AUTOSAR XML (schema 00053)
package /Application
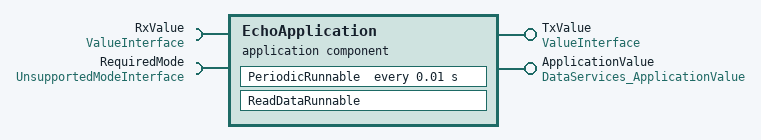
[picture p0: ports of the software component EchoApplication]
  application sw component type EchoApplication
    require port RxValue: nonqueued-receiver-com-spec{data-element=Value, alive-timeout=0.03, handle-never-received=true, init-value=0}, required-interface=ValueInterface
    provide port TxValue: nonqueued-sender-com-spec{data-element=Value, init-value=0}, provided-interface=ValueInterface
    provide port ApplicationValue: server-com-spec{operation=ReadData, queue-length=1}, provided-interface=DataServices_ApplicationValue
    require port RequiredMode: required-interface=UnsupportedModeInterface
    behavior Behavior: data-type-mapping=ApplicationTypes
      timing event Periodic10ms: start-on-event=PeriodicRunnable, period=0.01
      operation invoked event ReadApplicationValue: start-on-event=ReadDataRunnable, operation=ApplicationValue.ReadData
      runnable PeriodicRunnable: symbol=EchoApplication_Periodic
        data-receive-point-by-arguments:
          access ReadRxValue: accessed-variable=RxValue.Value
        data-send-points:
          access WriteTxValue: accessed-variable=TxValue.Value
        mode-access-point mode-group=RequiredMode.Mode:
          ident ReadMode
      runnable ReadDataRunnable: symbol=EchoApplication_ReadData
  composition sw component type ReferenceComposition
    component EchoApplication: type=EchoApplication
    component DcmService: type=DcmService
    connect EchoApplication.ApplicationValue -> DcmService.ApplicationValue
  mode declaration group UnsupportedModes: initial-mode=Idle
    mode Idle
  mode switch interface UnsupportedModeInterface
    mode group Mode: type=UnsupportedModes
